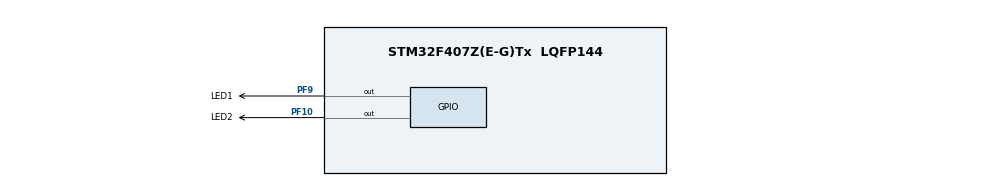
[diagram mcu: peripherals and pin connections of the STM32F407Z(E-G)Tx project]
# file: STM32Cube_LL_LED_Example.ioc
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Mcu.Family=STM32F4
Mcu.Name=STM32F407Z(E-G)Tx
Mcu.Package=LQFP144
NVIC.PriorityGroup=NVIC_PRIORITYGROUP_4
PF10.GPIO_Label=LED2
PF10.GPIO_PuPd=GPIO_PULLUP
PF10.GPIO_Speed=GPIO_SPEED_FREQ_VERY_HIGH
PF10.PinState=GPIO_PIN_SET
PF10.Signal=GPIO_Output
PF9.GPIO_Label=LED1
PF9.GPIO_ModeDefaultOutputPP=GPIO_MODE_OUTPUT_PP
PF9.GPIO_PuPd=GPIO_PULLUP
PF9.GPIO_Speed=GPIO_SPEED_FREQ_VERY_HIGH
PF9.PinState=GPIO_PIN_SET
PF9.Signal=GPIO_Output
PH0-OSC_IN.Mode=HSE-External-Oscillator
PH0-OSC_IN.Signal=RCC_OSC_IN
PH1-OSC_OUT.Mode=HSE-External-Oscillator
PH1-OSC_OUT.Signal=RCC_OSC_OUT
ProjectManager.HeapSize=0x200
ProjectManager.StackSize=0x400
ProjectManager.TargetToolchain=MDK-ARM V5
RCC.48MHZClocksFreq_Value=84000000
RCC.AHBFreq_Value=168000000
RCC.APB1CLKDivider=RCC_HCLK_DIV4
RCC.APB1Freq_Value=42000000
RCC.APB1TimFreq_Value=84000000
RCC.APB2CLKDivider=RCC_HCLK_DIV2
RCC.APB2Freq_Value=84000000
RCC.APB2TimFreq_Value=168000000
RCC.CortexFreq_Value=168000000
RCC.HCLKFreq_Value=168000000
RCC.HSE_VALUE=8000000
RCC.HSI_VALUE=16000000
RCC.LSE_VALUE=32768
RCC.PLLM=8
RCC.PLLN=336
RCC.PLLSourceVirtual=RCC_PLLSOURCE_HSE
RCC.SYSCLKFreq_VALUE=168000000
RCC.SYSCLKSource=RCC_SYSCLKSOURCE_PLLCLK
RCC.VCOOutputFreq_Value=336000000
board=STM32Cube_LL_LED_Example

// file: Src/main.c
/**
  ******************************************************************************
  * File Name          : main.c
  * Description        : Main program body
  ******************************************************************************
  ** This notice applies to any and all portions of this file
  * that are not between comment pairs USER CODE BEGIN and
  * USER CODE END. Other portions of this file, whether
  * inserted by the user or by software development tools
  * are owned by their respective copyright owners.
  *
  * COPYRIGHT(c) 2018 STMicroelectronics
  *
  * Redistribution and use in source and binary forms, with or without modification,
  * are permitted provided that the following conditions are met:
  *   1. Redistributions of source code must retain the above copyright notice,
  *      this list of conditions and the following disclaimer.
  *   2. Redistributions in binary form must reproduce the above copyright notice,
  *      this list of conditions and the following disclaimer in the documentation
  *      and/or other materials provided with the distribution.
  *   3. Neither the name of STMicroelectronics nor the names of its contributors
  *      may be used to endorse or promote products derived from this software
  *      without specific prior written permission.
  *
  * THIS SOFTWARE IS PROVIDED BY THE COPYRIGHT HOLDERS AND CONTRIBUTORS "AS IS"
  * AND ANY EXPRESS OR IMPLIED WARRANTIES, INCLUDING, BUT NOT LIMITED TO, THE
  * IMPLIED WARRANTIES OF MERCHANTABILITY AND FITNESS FOR A PARTICULAR PURPOSE ARE
  * DISCLAIMED. IN NO EVENT SHALL THE COPYRIGHT HOLDER OR CONTRIBUTORS BE LIABLE
  * FOR ANY DIRECT, INDIRECT, INCIDENTAL, SPECIAL, EXEMPLARY, OR CONSEQUENTIAL
  * DAMAGES (INCLUDING, BUT NOT LIMITED TO, PROCUREMENT OF SUBSTITUTE GOODS OR
  * SERVICES; LOSS OF USE, DATA, OR PROFITS; OR BUSINESS INTERRUPTION) HOWEVER
  * CAUSED AND ON ANY THEORY OF LIABILITY, WHETHER IN CONTRACT, STRICT LIABILITY,
  * OR TORT (INCLUDING NEGLIGENCE OR OTHERWISE) ARISING IN ANY WAY OUT OF THE USE
  * OF THIS SOFTWARE, EVEN IF ADVISED OF THE POSSIBILITY OF SUCH DAMAGE.
  *
  ******************************************************************************
  */

#include "main.h"
#include "gpio.h"

/* USER CODE BEGIN PV */
/* Private variables ---------------------------------------------------------*/

/* USER CODE END PV */

static void LL_Init(void);
void SystemClock_Config(void);

/* USER CODE BEGIN PFP */
/* Private function prototypes -----------------------------------------------*/

/* USER CODE END PFP */

int main(void)
{

  /* MCU Configuration----------------------------------------------------------*/

  /* Reset of all peripherals, Initializes the Flash interface and the Systick. */
  LL_Init();

  /* Configure the system clock */
  SystemClock_Config();

  /* Initialize all configured peripherals */
  MX_GPIO_Init();

  /* Infinite loop */
  while (1)
  {

  /* USER CODE BEGIN 3 */
    LL_mDelay(500);
    LL_GPIO_TogglePin(LED1_GPIO_Port, LED1_Pin);
    LL_GPIO_TogglePin(LED2_GPIO_Port, LED2_Pin);
  }
  /* USER CODE END 3 */

}

static void LL_Init(void)
{

  NVIC_SetPriorityGrouping(NVIC_PRIORITYGROUP_4);

  /* System interrupt init*/
  /* MemoryManagement_IRQn interrupt configuration */
  NVIC_SetPriority(MemoryManagement_IRQn, NVIC_EncodePriority(NVIC_GetPriorityGrouping(),0, 0));
  /* BusFault_IRQn interrupt configuration */
  NVIC_SetPriority(BusFault_IRQn, NVIC_EncodePriority(NVIC_GetPriorityGrouping(),0, 0));
  /* UsageFault_IRQn interrupt configuration */
  NVIC_SetPriority(UsageFault_IRQn, NVIC_EncodePriority(NVIC_GetPriorityGrouping(),0, 0));
  /* SVCall_IRQn interrupt configuration */
  NVIC_SetPriority(SVCall_IRQn, NVIC_EncodePriority(NVIC_GetPriorityGrouping(),0, 0));
  /* DebugMonitor_IRQn interrupt configuration */
  NVIC_SetPriority(DebugMonitor_IRQn, NVIC_EncodePriority(NVIC_GetPriorityGrouping(),0, 0));
  /* PendSV_IRQn interrupt configuration */
  NVIC_SetPriority(PendSV_IRQn, NVIC_EncodePriority(NVIC_GetPriorityGrouping(),0, 0));
  /* SysTick_IRQn interrupt configuration */
  NVIC_SetPriority(SysTick_IRQn, NVIC_EncodePriority(NVIC_GetPriorityGrouping(),0, 0));

}

/** System Clock Configuration
*/
void SystemClock_Config(void)
{

  LL_FLASH_SetLatency(LL_FLASH_LATENCY_5);

  if(LL_FLASH_GetLatency() != LL_FLASH_LATENCY_5)
  {
  Error_Handler();
  }
  LL_PWR_SetRegulVoltageScaling(LL_PWR_REGU_VOLTAGE_SCALE1);

  LL_RCC_HSE_Enable();

   /* Wait till HSE is ready */
  while(LL_RCC_HSE_IsReady() != 1)
  {

  }
  LL_RCC_PLL_ConfigDomain_SYS(LL_RCC_PLLSOURCE_HSE, LL_RCC_PLLM_DIV_8, 336, LL_RCC_PLLP_DIV_2);

  LL_RCC_PLL_Enable();

   /* Wait till PLL is ready */
  while(LL_RCC_PLL_IsReady() != 1)
  {

  }
  LL_RCC_SetAHBPrescaler(LL_RCC_SYSCLK_DIV_1);

  LL_RCC_SetAPB1Prescaler(LL_RCC_APB1_DIV_4);

  LL_RCC_SetAPB2Prescaler(LL_RCC_APB2_DIV_2);

  LL_RCC_SetSysClkSource(LL_RCC_SYS_CLKSOURCE_PLL);

   /* Wait till System clock is ready */
  while(LL_RCC_GetSysClkSource() != LL_RCC_SYS_CLKSOURCE_STATUS_PLL)
  {

  }
  LL_Init1msTick(168000000);

  LL_SYSTICK_SetClkSource(LL_SYSTICK_CLKSOURCE_HCLK);

  LL_SetSystemCoreClock(168000000);

  /* SysTick_IRQn interrupt configuration */
  NVIC_SetPriority(SysTick_IRQn, NVIC_EncodePriority(NVIC_GetPriorityGrouping(),0, 0));
}

void _Error_Handler(char * file, int line)
{
  while(1)
  {
  }
}

/************************ (C) COPYRIGHT STMicroelectronics *****END OF FILE****/
